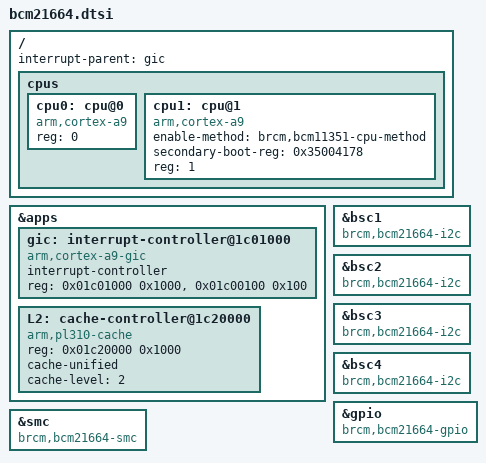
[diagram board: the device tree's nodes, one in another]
// SPDX-License-Identifier: GPL-2.0-only
// Copyright (C) 2014 Broadcom Corporation

#include "bcm2166x-common.dtsi"

/ {
	interrupt-parent = <&gic>;

	cpus {
		#address-cells = <1>;
		#size-cells = <0>;

		cpu0: cpu@0 {
			device_type = "cpu";
			compatible = "arm,cortex-a9";
			reg = <0>;
		};

		cpu1: cpu@1 {
			device_type = "cpu";
			compatible = "arm,cortex-a9";
			enable-method = "brcm,bcm11351-cpu-method";
			secondary-boot-reg = <0x35004178>;
			reg = <1>;
		};
	};
};

&apps {
		gic: interrupt-controller@1c01000 {
			compatible = "arm,cortex-a9-gic";
			#interrupt-cells = <3>;
			#address-cells = <0>;
			interrupt-controller;
			reg = <0x01c01000 0x1000>,
				  <0x01c00100 0x100>;
		};

		L2: cache-controller@1c20000 {
			compatible = "arm,pl310-cache";
			reg = <0x01c20000 0x1000>;
			cache-unified;
			cache-level = <2>;
		};
};

&bsc1 {
	compatible = "brcm,bcm21664-i2c", "brcm,kona-i2c";
};

&bsc2 {
	compatible = "brcm,bcm21664-i2c", "brcm,kona-i2c";
};

&bsc3 {
	compatible = "brcm,bcm21664-i2c", "brcm,kona-i2c";
};

&bsc4 {
	compatible = "brcm,bcm21664-i2c", "brcm,kona-i2c";
};

&gpio {
	compatible = "brcm,bcm21664-gpio", "brcm,kona-gpio";
};

&smc {
	compatible = "brcm,bcm21664-smc", "brcm,kona-smc";
};
